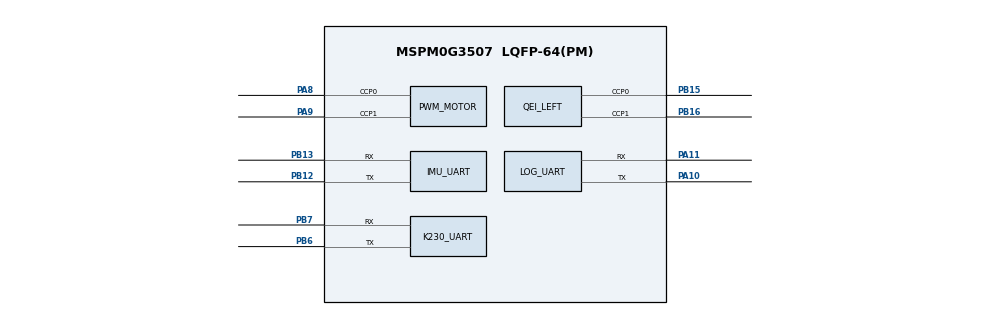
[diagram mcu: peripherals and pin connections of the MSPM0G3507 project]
/**
 * MSPM0G3507 自平衡瞄准小车 —— 阶段 0 引脚定义
 *
 * 本文件由 docs/TaskLog/Stage0-PinAllocation.md 中的"引脚分配总表"派生而来，
 * 任何引脚改动必须先改文档再改本文件，保持双向一致。
 *
 * 重要硬件约束（来自 SDK QEIMSPM0.syscfg.js + Common.js getTimerInstances）：
 *   MSPM0G3507 上能配置硬件 QEI 的定时器只有 TIMG8（TIMG9/10/11 在本器件不存在）。
 *   因此只有左编码器走硬件 QEI（TIMG8 + J12），右编码器在阶段 0 暂以 GPIO + 双边沿
 *   中断方式落到 PA12/PA13；阶段 2 再决定是否升级为 CAPTURE 模式。
 */

//@cliArgs --device "MSPM0G350X" --package "LQFP-64(PM)" --part "Default"
//@v2CliArgs --device "MSPM0G3507" --package "LQFP-64(PM)"
// @cliArgs --board /ti/boards/LP_MSPM0G3507 --rtos nortos

/* ========================================================================== */
/* 模块导入                                                                    */
/* ========================================================================== */
const SYSCTL = scripting.addModule("/ti/driverlib/SYSCTL");
const GPIO   = scripting.addModule("/ti/driverlib/GPIO", {}, false);
const PWM    = scripting.addModule("/ti/driverlib/PWM",  {}, false);
const QEI    = scripting.addModule("/ti/driverlib/QEI",  {}, false);
const UART   = scripting.addModule("/ti/driverlib/UART", {}, false);
const ADC12  = scripting.addModule("/ti/driverlib/ADC12", {}, false);

const Board  = scripting.addModule("/ti/driverlib/Board", {}, false);

/* I2C 模块在 Stage 1.5 已下线：原 MPU6050 占用 I2C1 (PB2/PB3)，但开发板
 * PB2/PB3 未板载 4.7 kΩ 上拉电阻，I²C 总线全开路；为避免焊接修复风险
 * 改用 ATK-MS901M（UART2 / PA21 TX / PA22 RX / 115200 8N1）。详见
 * docs/TaskLog/Stage1.5-IMU-Swap-MS901M.md。 */

/* ========================================================================== */
/* 时钟                                                                        */
/* ========================================================================== */
SYSCTL.forceDefaultClkConfig = true;

/* ========================================================================== */
/* GPIO 由 BSP 接管，不再走 SysConfig                                          */
/*                                                                              */
/* 历史背景（详见 docs/TaskLog/Stage1-IMU-BT-Telemetry.md §8.5）：              */
/*   SDK 2.10 (sysconfig 1.27.0) 在 GPIO module 的 codegen 路径上，对          */
/*   "multi-pad / dual-bonded" 引脚（LQFP-64 上 PA13/15/16/18/26/27、         */
/*   PB22/26/27 等高 PINCM 引脚）存在体系性 bug：                              */
/*     · Common.js getGPIOPortMultiPad()/getGPINumberMultiPad() 走             */
/*       identifyPadIndex() 分支；                                             */
/*     · 该函数在 GPIO 路径下 (peripheralName === undefined) 用                */
/*       `peripheralName + "." + pinInterfaceName` 去 indexOf，常量化为        */
/*       "undefined.undefined"，永远 -1，结果 modeMiddleIndex 后回退到         */
/*       padIndex = 0，再被 `find(item => item.mode === "1")` 第一项命中       */
/*       到 alternate pad（如 PB26 → PC1，PA15 → PA1），生成出来的 .h 里      */
/*       PIN 与 .c 里 portName 全部错位（典型症状：DL_GPIO_clearPins(GPIOC,   */
/*       ...) 编译失败 / LED_R 与 LED_G 撞同一个 PIN_1）。                    */
/*     · 试过 `pin.$assign="PB26"`、`assignedPin="26"` + instance.port、       */
/*       拆 GPIO_OUT_A/B 等 4 种写法，**都救不回来**——bug 在 codegen，       */
/*       不在 syntax。peripheral 引脚（UART/I2C/PWM/QEI/ADC）走                */
/*       getDualBondedPadFunction，那条路径正常，故 syscfg 仅留 peripheral。  */
/*                                                                              */
/* 因此本工程：                                                                 */
/*   · syscfg 不再 addInstance() GPIO 模块，全部 14 个业务 GPIO 引脚由         */
/*     `template/hardware/bsp_gpio.[ch]` 用 IOMUX_PINCMxx + DL_GPIO_PIN_<bit> */
/*     直接初始化；                                                            */
/*   · 业务代码用 BSP_LED_R_PORT/PIN、BSP_BUZZER_PORT/PIN 等宏访问，名字与    */
/*     pin 分配文档（Stage0-PinAllocation.md）一一对应；                      */
/*   · GPIO power 启用由 SDK 在 SYSCFG_DL_initPower() 内自动包含（peripheral  */
/*     pin 占用了 PORTA/PORTB，触发 DL_GPIO_enablePower(GPIOA/B)）。           */
/* ========================================================================== */

/* ========================================================================== */
/* TIMA0 PWM —— TB6612 双电机驱动                                              */
/*   PWMA (Left)  = PA8 = TIMA0_C0                                             */
/*   PWMB (Right) = PA9 = TIMA0_C1                                             */
/*   频率 20 kHz @ MCLK 32 MHz (默认 SYSOSC)                                   */
/*     LOAD = 32e6 / 20e3 - 1 = 1599                                           */
/*   若日后切换到 80 MHz HFXT，请把 timerCount 改为 3999 并同步更新本文档      */
/* ========================================================================== */
const PWM_MOTOR = PWM.addInstance();
PWM_MOTOR.$name                            = "PWM_MOTOR";
PWM_MOTOR.timerCount                       = 1599;
PWM_MOTOR.timerStartTimer                  = true;
PWM_MOTOR.peripheral.$assign               = "TIMA0";
PWM_MOTOR.peripheral.ccp0Pin.$assign       = "PA8";
PWM_MOTOR.peripheral.ccp1Pin.$assign       = "PA9";
PWM_MOTOR.PWM_CHANNEL_0.$name              = "PWM_MOTOR_LEFT";
PWM_MOTOR.PWM_CHANNEL_1.$name              = "PWM_MOTOR_RIGHT";
PWM_MOTOR.PWM_CHANNEL_0.dutyCycle          = 0;
PWM_MOTOR.PWM_CHANNEL_1.dutyCycle          = 0;

/* ========================================================================== */
/* TIMG8 QEI —— 左编码器 (Stage 2.3 起从 J12 迁到 BoosterPack 排针)            */
/*   PHA   = PB15 (BP J4.34) = TIMG8_CCP0  (mux func 5, datasheet PINMUX 表)   */
/*   PHB   = PB16 (BP J4.40) = TIMG8_CCP1  (mux func 5, datasheet PINMUX 表)   */
/*   IDX   = (不接，2-Pin Mode)                                                */
/*                                                                              */
/*   迁移背景（Stage 2.3 / 2026-05-09）：                                       */
/*     原方案 PA29/PA30/PB14 全部走 LaunchPad J12 QEI 接口排针，但 J12 排针    */
/*     在板子上**未焊接**（出厂状态），无法直接插线；同时 PB14 不在 BP 上、    */
/*     PA29/PA30 也不在 BP 上，三脚都需要焊接代价。                            */
/*                                                                              */
/*     Stage 2.3 评估发现 BoosterPack 上有空闲 PB15/PB16 可作 TIMG8_C0/C1：    */
/*       · datasheet PINMUX 表：                                                */
/*           PB15 = TIMG8_C0 [func 5]                                          */
/*           PB16 = TIMG8_C1 [func 5]                                          */
/*       · BP 排针位置：PB15 = J4.34、PB16 = J4.40（同列相邻）                 */
/*       · 当前两根都空闲（蓝牙 Stage 1.6 下线后 PB15/PB16 进入预留池）        */
/*     IDX 同步省略：GB370 编码器无 Z 相，DL_TIMER_QEI_MODE_2_INPUT 即可，      */
/*     X4 解码精度（1320 cnt/rev）不变。                                       */
/*                                                                              */
/*   关于 multi-pad codegen bug：PB15/PB16 是 multi-pad 引脚，但 SDK bug 仅    */
/*   影响 SysConfig GPIO 模块路径（详见本文 §"GPIO 由 BSP 接管"注释块），      */
/*   peripheral 模块（QEI/PWM/UART/ADC）走 getDualBondedPadFunction 安全。      */
/*                                                                              */
/*   注：MSPM0G3507 上仅 TIMG8 支持硬件 QEI；右编码器只能软件模拟。            */
/*                                                                              */
/*   随之释放（不可再被 GPIO/外设占用前需更新 Stage0 §3.3 预留表）：           */
/*     · J12 跳线：保留 OFF / 不再使用                                         */
/*     · PA29 (LQFP 36) / PA30 (LQFP 37) / PB14 (LQFP 2) 进入预留              */
/* ========================================================================== */
const QEI_LEFT = QEI.addInstance();
QEI_LEFT.$name                             = "QEI_LEFT";
QEI_LEFT.enableIndexInput                  = false;
QEI_LEFT.loadValue                         = 0xFFFF;
QEI_LEFT.timerStartTimer                   = true;
QEI_LEFT.peripheral.$assign                = "TIMG8";
QEI_LEFT.peripheral.ccp0Pin.$assign        = "PB15";
QEI_LEFT.peripheral.ccp1Pin.$assign        = "PB16";

/* ========================================================================== */
/* UART3 —— ATK-MS901M 姿态传感器 (Stage 1.6 引脚集中化重排)                   */
/*   TX = PB12, RX = PB13, 115200 8N1, FIFO + RX 中断                          */
/*                                                                              */
/*   背景：开发板 PB2/PB3 缺 I²C 上拉电阻，I2C1 全开路；Stage 1.5 改用 MS901M  */
/*         （自带 EKF，串口主动上报 0x01 RPY / 0x02 四元数 / 0x03 raw gyro+    */
/*         accel / 0x04 mag+temp / 0x05 baro+alt），原方案占 UART2 + PA21/PA22。 */
/*                                                                              */
/*   Stage 1.6 重排原因：PA21（LQFP pin 17）**未引到 BoosterPack**，仅可从板底 */
/*         J23-J28 引脚扩展接头取出（焊接成本高）。复核 LaunchPad User's Guide  */
/*         图 2-10 BoosterPack 引脚布局后，把 IMU 串口从 UART2/PA21/PA22 整体  */
/*         迁到 UART3/PB12/PB13——PB12 = J4.32、PB13 = J2.26，二者均为开放排针 */
/*         直接接出，且都是单 pad（PINCM29 / PINCM30），不踩 SDK 2.10 multi-pad */
/*         codegen bug（详见 docs/TaskLog/Stage1-IMU-BT-Telemetry.md §8.5）。   */
/*                                                                              */
/*   蓝牙模块（原 UART_BT 占用 UART3 + PB12/PB13）已在 Stage 1.6 整体下线，    */
/*   引脚释放给 IMU；遥测可视化方案改为 XDS-UART (UART0) printf + 上位机串口   */
/*   数据流，详见 docs/TaskLog/Stage1.5-IMU-Swap-MS901M.md §11 Stage 1.6 重排。 */
/*                                                                              */
/*   不开 DMA：MS901M 帧组合典型 100 Hz × ~50 B ≈ 40 kbps，远低于 115200 链路 */
/*           容量；UART3 RX FIFO + 半满中断 + 256 B 环缓即可，无需 DMA 通道    */
/*           （DMA 通道留给 K230 UART1）。                                      */
/*                                                                              */
/*   注：MS901M 默认出厂 115200 8N1 主动上报 0x01..0x05 五帧；上位机一次性配置 */
/*       后永久写入 EEPROM，详见 docs/TaskLog/Stage1.5-IMU-Swap-MS901M.md。    */
/* ========================================================================== */
const IMU_UART = UART.addInstance();
IMU_UART.$name                             = "UART_IMU";
IMU_UART.targetBaudRate                    = 115200;
IMU_UART.enableFIFO                        = true;
IMU_UART.enabledInterrupts                 = ["RX"];
IMU_UART.peripheral.$assign                = "UART3";
IMU_UART.peripheral.txPin.$assign          = "PB12";
IMU_UART.peripheral.rxPin.$assign          = "PB13";

/* ========================================================================== */
/* UART0 —— 开发期日志 (XDS-UART 桥)                                           */
/*   TX = PA10, RX = PA11, 115200 8N1                                          */
/* ========================================================================== */
const LOG_UART = UART.addInstance();
LOG_UART.$name                             = "UART_LOG";
LOG_UART.targetBaudRate                    = 115200;
LOG_UART.peripheral.$assign                = "UART0";
LOG_UART.peripheral.txPin.$assign          = "PA10";
LOG_UART.peripheral.rxPin.$assign          = "PA11";

/* ========================================================================== */
/* UART1 —— K230 通讯 (DMA TX/RX)                                              */
/*   TX = PB6, RX = PB7, 921600 8N1                                            */
/*   注：PB6/PB7 在 MSPM0G3507 LQFP-64 上是 UART1 引脚（不是 UART3）。         */
/*       UART3 在本器件上的合法 TX/RX 组合是 PA26/PA25 或 PB12/PA13 等，       */
/*       与本项目的 TB6612 BIN1/BIN2 / 右编码器 B 相冲突，因此用 UART1。       */
/*   DMA 子模块由 SDK 在 enabledDMA*Triggers != "None" 时自动实例化            */
/* ========================================================================== */
const K230_UART = UART.addInstance();
K230_UART.$name                            = "UART_K230";
K230_UART.targetBaudRate                   = 921600;
K230_UART.enableFIFO                       = true;
K230_UART.enabledDMARXTriggers             = "DL_UART_DMA_INTERRUPT_RX";
K230_UART.enableDMARX                      = true;
K230_UART.enabledDMATXTriggers             = "DL_UART_DMA_INTERRUPT_TX";
K230_UART.enableDMATX                      = true;
K230_UART.peripheral.$assign               = "UART1";
K230_UART.peripheral.txPin.$assign         = "PB6";
K230_UART.peripheral.rxPin.$assign         = "PB7";

/* ========================================================================== */
/* 蓝牙串口（UART_BT / UART3 / PB12 / PB13）已在 Stage 1.6 整体下线：         */
/*   原占用的 PB12/PB13 释放给 IMU MS901M（UART_IMU 改用 UART3，见上方）。     */
/*   遥测路径切换为 XDS-UART (UART0) printf + 上位机串口工具直接读取，         */
/*   VOFA+ JustFloat 二进制流暂停；如未来需要无线遥测，可走 K230 BLE 透传     */
/*   或 USB Type-C HID/CDC，不再占用主控 UART。                                */
/*                                                                              */
/*   引脚迁移决策与重排根因详见：                                              */
/*     · docs/TaskLog/Stage1.5-IMU-Swap-MS901M.md §11（Stage 1.6 引脚重排）   */
/*     · docs/TaskLog/Stage0-PinAllocation.md v0.8（蓝牙整段下线 / IMU UART3）*/
/* ========================================================================== */

/* ========================================================================== */
/* ADC0 —— 电池电压分压采样                                                    */
/*   BAT_VSENSE = PB24 = ADC0_5                                                */
/*   12-bit, 软件触发, 参考 = VDDA (3.3 V)                                     */
/*                                                                              */
/*   重要（Stage 2.4 / 2026-05-09 修复）：                                       */
/*     早期版本未显式设置 sampleTime，SDK 生成的 SCOMP0 默认 = 0 周期 → ADC   */
/*     无法完成转换，`MEM0_RESULT_LOADED` 标志永不置位 → bsp_battery 永远拿不   */
/*     到值、EMA 留在 0 mV → app_safety 进入 LOW_BAT_STOP 紧急停车。            */
/*     现修正：sampleTime0 = 26 cycles（≈ 800 ns @ 32 MHz ULPCLK），单端 12-bit*/
/*     最低需要 ~14 ULPCLK 周期采样 + 14 周期转换；26 周期裕度足够，整个 ADC    */
/*     转换 ≤ 1.3 µs/次。                                                       */
/*   参考：MSPM0G3507 datasheet §13.5 "ADC Acquisition Time" + SDK 例程         */
/*         `adc12_single_conversion_LP_MSPM0G3507_nortos_ticlang/`              */
/* ========================================================================== */
const BAT_ADC = ADC12.addInstance();
BAT_ADC.$name                              = "ADC_BAT";
BAT_ADC.sampClkSrc                         = "DL_ADC12_CLOCK_ULPCLK";
BAT_ADC.resolution                         = "DL_ADC12_SAMP_CONV_RES_12_BIT";
BAT_ADC.adcMem0chansel                     = "DL_ADC12_INPUT_CHAN_5";
BAT_ADC.sampleTime0                        = "1 us";
BAT_ADC.peripheral.$assign                 = "ADC0";
BAT_ADC.peripheral.adcPin5.$assign         = "PB24";
